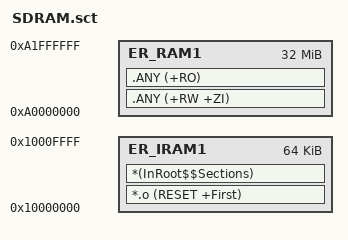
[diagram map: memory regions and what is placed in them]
; *************************************************************
; *** Scatter-Loading Description File generated by uVision ***
; *************************************************************

LR_IRAM1 0x10000000 0x00010000  {    ; load region size_region
  ER_IRAM1 0x10000000 0x00010000  {
   *.o (RESET +First)
   *(InRoot$$Sections)
  }
}

LR_RAM1 0xA0000000 0x02000000  {    ; load region size_region
  ER_RAM1 0xA0000000 0x02000000  {
   .ANY (+RW +ZI)
   .ANY (+RO)
  }
}
